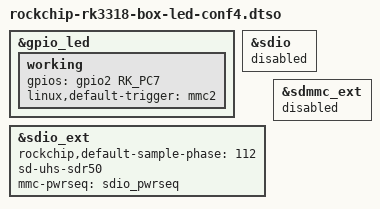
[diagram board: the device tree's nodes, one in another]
/dts-v1/;
/plugin/;

#include <dt-bindings/gpio/gpio.h>
#include <dt-bindings/input/input.h>
#include <dt-bindings/pinctrl/rockchip.h>

/**
 * Generic rk3318 board with sdio bus on sdmmc_ext connector
 */

&gpio_led {

	working {
		gpios = <&gpio2 RK_PC7 GPIO_ACTIVE_HIGH>;
		linux,default-trigger = "mmc2";
	};

};

/*
 * Following section enables the sdio bus on sdmmc_ext controller
 */
&sdio {
	/delete-property/ mmc-pwrseq;
	status = "disabled";
};

&sdio_ext {
	rockchip,default-sample-phase = <112>;
	sd-uhs-sdr50;
	mmc-pwrseq = <&sdio_pwrseq>;
	status = "okay";
};

&sdmmc_ext {
	status = "disabled";
};
